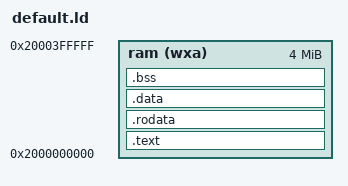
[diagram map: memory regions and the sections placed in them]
OUTPUT_ARCH("riscv")

ENTRY(_start)

MEMORY {
    ram (wxa) : ORIGIN = 0x2000000000, LENGTH = 4M
}

PHDRS
{
  text PT_LOAD;
  data PT_LOAD;
  bss PT_LOAD;
}

SECTIONS {
    .text : {
        PROVIDE(_text_start = .);
        *(.text .text.*)
        PROVIDE(_text_end = .);
    } > ram :text

    .rodata : {
        PROVIDE(_rodata_start = .);
        *(.rodata .rodata.*)
        PROVIDE(_rodata_end = .);
    } > ram :text

    .data : {
        PROVIDE(_data_start = .);
        *(.sdata .sdata.*) *(.data .data.*)
        PROVIDE(_data_end = .);
    } > ram :text
    
    .bss : {
        PROVIDE(_bss_start = .);
        *(.sbss .sbss.*) *(.bss .bss.*)
        PROVIDE(_bss_end = .);
    } > ram :text

    PROVIDE(_memory_start = ORIGIN(ram));
    PROVIDE(_memory_end = ORIGIN(ram) + LENGTH(ram));

    /* PROVIDE(_stack_start = _memory_end); */
    PROVIDE(_stack_end = 0x2000010000);
}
